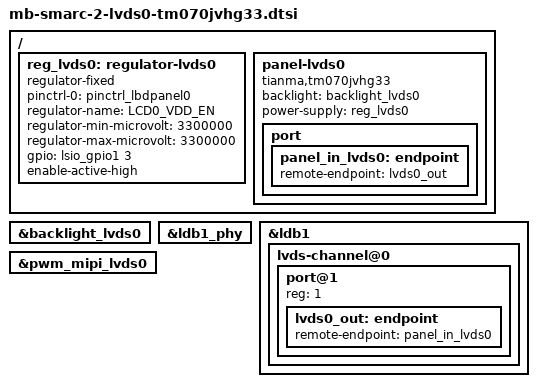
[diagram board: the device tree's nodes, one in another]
// SPDX-License-Identifier: (GPL-2.0-or-later OR MIT)
/*
 * Copyright 2018-2022 TQ-Systems GmbH
 * Author: Alexander Stein <linux@ew.tq-group.com>
 */

/ {
	reg_lvds0: regulator-lvds0 {
		compatible = "regulator-fixed";
		pinctrl-names = "default";
		pinctrl-0 = <&pinctrl_lbdpanel0>;
		regulator-name = "LCD0_VDD_EN";
		regulator-min-microvolt = <3300000>;
		regulator-max-microvolt = <3300000>;
		gpio = <&lsio_gpio1 3 GPIO_ACTIVE_HIGH>;
		enable-active-high;
	};

	panel-lvds0 {
		compatible = "tianma,tm070jvhg33";
		backlight = <&backlight_lvds0>;
		power-supply = <&reg_lvds0>;
		status = "okay";

		port {
			panel_in_lvds0: endpoint {
				remote-endpoint = <&lvds0_out>;
			};
		};
	};
};

&backlight_lvds0 {
	status = "okay";
};

&ldb1_phy {
	status = "okay";
};

&ldb1 {
	status = "okay";

	lvds-channel@0 {
		status = "okay";

		port@1 {
			reg = <1>;

			lvds0_out: endpoint {
				remote-endpoint = <&panel_in_lvds0>;
			};
		};
	};
};

&pwm_mipi_lvds0 {
	status = "okay";
};
